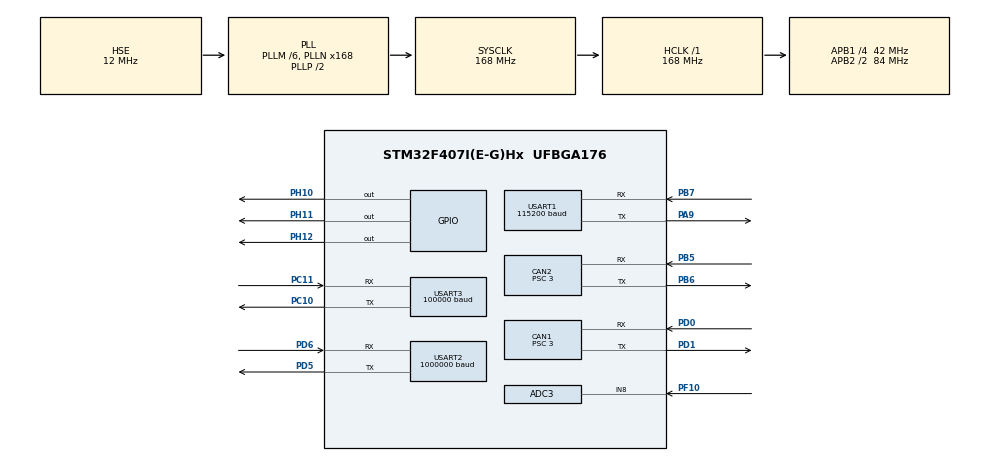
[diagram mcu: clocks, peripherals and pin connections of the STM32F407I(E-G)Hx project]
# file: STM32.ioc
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ADC3.Channel-1\#ChannelRegularConversion=ADC_CHANNEL_8
ADC3.EnableAnalogWatchDog=false
ADC3.ExternalTrigConv=ADC_EXTERNALTRIGCONV_T3_TRGO
ADC3.NbrOfConversionFlag=1
ADC3.Rank-1\#ChannelRegularConversion=1
ADC3.SamplingTime-1\#ChannelRegularConversion=ADC_SAMPLETIME_28CYCLES
CAN1.ABOM=ENABLE
CAN1.BS1=CAN_BS1_10TQ
CAN1.BS2=CAN_BS2_3TQ
CAN1.CalculateBaudRate=1000000
CAN1.CalculateTimeBit=1000
CAN1.CalculateTimeQuantum=71.42857142857143
CAN1.Prescaler=3
CAN2.ABOM=ENABLE
CAN2.BS1=CAN_BS1_10TQ
CAN2.BS2=CAN_BS2_3TQ
CAN2.CalculateBaudRate=1000000
CAN2.CalculateTimeBit=1000
CAN2.CalculateTimeQuantum=71.42857142857143
CAN2.Prescaler=3
Dma.Request0=USART3_RX
Dma.Request1=USART3_TX
Dma.USART3_RX.0.Direction=DMA_PERIPH_TO_MEMORY
Dma.USART3_RX.0.FIFOMode=DMA_FIFOMODE_DISABLE
Dma.USART3_RX.0.Instance=DMA1_Stream1
Dma.USART3_RX.0.MemDataAlignment=DMA_MDATAALIGN_BYTE
Dma.USART3_RX.0.MemInc=DMA_MINC_ENABLE
Dma.USART3_RX.0.Mode=DMA_NORMAL
Dma.USART3_RX.0.PeriphDataAlignment=DMA_PDATAALIGN_BYTE
Dma.USART3_RX.0.PeriphInc=DMA_PINC_DISABLE
Dma.USART3_RX.0.Priority=DMA_PRIORITY_LOW
Dma.USART3_TX.1.Direction=DMA_MEMORY_TO_PERIPH
Dma.USART3_TX.1.FIFOMode=DMA_FIFOMODE_DISABLE
Dma.USART3_TX.1.Instance=DMA1_Stream3
Dma.USART3_TX.1.MemDataAlignment=DMA_MDATAALIGN_BYTE
Dma.USART3_TX.1.MemInc=DMA_MINC_ENABLE
Dma.USART3_TX.1.Mode=DMA_NORMAL
Dma.USART3_TX.1.PeriphDataAlignment=DMA_PDATAALIGN_BYTE
Dma.USART3_TX.1.PeriphInc=DMA_PINC_DISABLE
Dma.USART3_TX.1.Priority=DMA_PRIORITY_LOW
Mcu.Family=STM32F4
Mcu.Name=STM32F407I(E-G)Hx
Mcu.Package=UFBGA176
NVIC.CAN1_RX0_IRQn=true\:0\:0\:false\:false\:true\:true\:true\:true
NVIC.CAN1_RX1_IRQn=true\:0\:0\:false\:false\:true\:true\:true\:true
NVIC.CAN1_SCE_IRQn=true\:0\:0\:false\:false\:true\:true\:true\:true
NVIC.CAN1_TX_IRQn=true\:0\:0\:false\:false\:true\:true\:true\:true
NVIC.CAN2_RX0_IRQn=true\:0\:0\:false\:false\:true\:true\:true\:true
NVIC.CAN2_RX1_IRQn=true\:0\:0\:false\:false\:true\:true\:true\:true
NVIC.CAN2_SCE_IRQn=true\:0\:0\:false\:false\:true\:true\:true\:true
NVIC.CAN2_TX_IRQn=true\:0\:0\:false\:false\:true\:true\:true\:true
NVIC.DMA1_Stream1_IRQn=true\:0\:0\:false\:false\:true\:false\:true\:true
NVIC.DMA1_Stream3_IRQn=true\:0\:0\:false\:false\:true\:false\:true\:true
NVIC.PriorityGroup=NVIC_PRIORITYGROUP_4
NVIC.TIM6_DAC_IRQn=true\:0\:0\:false\:false\:true\:true\:true\:true
NVIC.TIM7_IRQn=true\:0\:0\:false\:false\:true\:true\:true\:true
NVIC.USART1_IRQn=true\:0\:0\:false\:false\:true\:true\:true\:true
NVIC.USART2_IRQn=true\:0\:0\:false\:false\:true\:true\:true\:true
NVIC.USART3_IRQn=true\:0\:0\:false\:false\:true\:true\:true\:true
PA10.Signal=USB_OTG_FS_ID
PA11.Signal=USB_OTG_FS_DM
PA13.Mode=Serial_Wire
PA13.Signal=SYS_JTMS-SWDIO
PA14.Mode=Serial_Wire
PA14.Signal=SYS_JTCK-SWCLK
PA9.Mode=Asynchronous
PA9.Signal=USART1_TX
PB5.Mode=CAN_Activate
PB5.Signal=CAN2_RX
PB6.Mode=CAN_Activate
PB6.Signal=CAN2_TX
PB7.Mode=Asynchronous
PB7.Signal=USART1_RX
PC10.Mode=Asynchronous
PC10.Signal=USART3_TX
PC11.Mode=Asynchronous
PC11.Signal=USART3_RX
PC8.Signal=S_TIM3_CH3
PD0.Mode=CAN_Activate
PD0.Signal=CAN1_RX
PD1.Mode=CAN_Activate
PD1.Signal=CAN1_TX
PD14.Signal=S_TIM4_CH3
PD5.Mode=Asynchronous
PD5.Signal=USART2_TX
PD6.Mode=Asynchronous
PD6.Signal=USART2_RX
PF10.Mode=IN8
PF10.Signal=ADC3_IN8
PG14.Signal=USART6_TX
PG9.Signal=USART6_RX
PH0-OSC_IN.Mode=HSE-External-Oscillator
PH0-OSC_IN.Signal=RCC_OSC_IN
PH1-OSC_OUT.Mode=HSE-External-Oscillator
PH1-OSC_OUT.Signal=RCC_OSC_OUT
PH10.Signal=GPIO_Output
PH11.Signal=GPIO_Output
PH12.Signal=GPIO_Output
ProjectManager.HeapSize=0x1000
ProjectManager.StackSize=0x2000
ProjectManager.TargetToolchain=MDK-ARM V5.32
RCC.48MHZClocksFreq_Value=48000000
RCC.AHBFreq_Value=168000000
RCC.APB1CLKDivider=RCC_HCLK_DIV4
RCC.APB1Freq_Value=42000000
RCC.APB1TimFreq_Value=84000000
RCC.APB2CLKDivider=RCC_HCLK_DIV2
RCC.APB2Freq_Value=84000000
RCC.APB2TimFreq_Value=168000000
RCC.CortexFreq_Value=168000000
RCC.HCLKFreq_Value=168000000
RCC.HSE_VALUE=12000000
RCC.HSI_VALUE=16000000
RCC.LSE_VALUE=32768
RCC.PLLM=6
RCC.PLLN=168
RCC.PLLQ=7
RCC.PLLSourceVirtual=RCC_PLLSOURCE_HSE
RCC.SYSCLKFreq_VALUE=168000000
RCC.SYSCLKSource=RCC_SYSCLKSOURCE_PLLCLK
RCC.VCOOutputFreq_Value=336000000
SH.S_TIM3_CH3.0=TIM3_CH3
SH.S_TIM4_CH3.0=TIM4_CH3
TIM3.TIM_MasterOutputTrigger=TIM_TRGO_UPDATE
TIM4.AutoReloadPreload=TIM_AUTORELOAD_PRELOAD_ENABLE
TIM5.Period=100-1
TIM6.AutoReloadPreload=TIM_AUTORELOAD_PRELOAD_DISABLE
TIM6.Period=1000-1
TIM6.Prescaler=84-1
TIM6.TIM_MasterOutputTrigger=TIM_TRGO_RESET
TIM7.AutoReloadPreload=TIM_AUTORELOAD_PRELOAD_DISABLE
TIM7.Period=1000-1
TIM7.Prescaler=84-1
USART1.BaudRate=115200
USART1.VirtualMode=VM_ASYNC
USART2.BaudRate=1000000
USART2.VirtualMode=VM_ASYNC
USART3.BaudRate=100000
USART3.VirtualMode=VM_ASYNC
VP_IWDG_VS_IWDG.Mode=IWDG_Activate
VP_TIM3_VS_ClockSourceINT.Mode=Internal
VP_TIM4_VS_ClockSourceINT.Mode=Internal
VP_TIM5_VS_ClockSourceINT.Mode=Internal
VP_TIM6_VS_ClockSourceINT.Mode=Enable_Timer
VP_TIM7_VS_ClockSourceINT.Mode=Enable_Timer
board=custom

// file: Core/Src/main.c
/* USER CODE BEGIN Header */
/**
  ******************************************************************************
  * @file           : main.c
  * @brief          : Main program body
  ******************************************************************************
  * @attention
  *
  * Copyright (c) 2023 STMicroelectronics.
  * All rights reserved.
  *
  * This software is licensed under terms that can be found in the LICENSE file
  * in the root directory of this software component.
  * If no LICENSE file comes with this software, it is provided AS-IS.
  *
  ******************************************************************************
  */
/* USER CODE END Header */
#include "main.h"
#include "adc.h"
#include "can.h"
#include "dma.h"
#include "iwdg.h"
#include "tim.h"
#include "usart.h"
#include "gpio.h"
#include "string.h"
#include "remote_control.h"

void SystemClock_Config(void);

int main(void)
{

  /* MCU Configuration--------------------------------------------------------*/

  /* Reset of all peripherals, Initializes the Flash interface and the Systick. */
  HAL_Init();

  /* Configure the system clock */
  SystemClock_Config();

  /* Initialize all configured peripherals */
  MX_GPIO_Init();
  MX_DMA_Init();
  MX_ADC3_Init();
  MX_CAN1_Init();
  MX_CAN2_Init();
  //MX_IWDG_Init();
  MX_TIM3_Init();
  MX_TIM4_Init();
  MX_TIM5_Init();
  MX_TIM6_Init();
  MX_TIM7_Init();
  MX_USART1_UART_Init();
  MX_USART2_UART_Init();
  MX_USART3_UART_Init();
  /* USER CODE BEGIN 2 */
    canFilterInit();
    HAL_UART_Receive_IT(&huart3,buffer,18);
  /* USER CODE END 2 */

  /* Infinite loop */
  while (1)
  {

  }
}

void SystemClock_Config(void)
{
  RCC_OscInitTypeDef RCC_OscInitStruct = {0};
  RCC_ClkInitTypeDef RCC_ClkInitStruct = {0};

  /** Configure the main internal regulator output voltage
  */
  __HAL_RCC_PWR_CLK_ENABLE();
  __HAL_PWR_VOLTAGESCALING_CONFIG(PWR_REGULATOR_VOLTAGE_SCALE1);

  /** Initializes the RCC Oscillators according to the specified parameters
  * in the RCC_OscInitTypeDef structure.
  */
  RCC_OscInitStruct.OscillatorType = RCC_OSCILLATORTYPE_LSI|RCC_OSCILLATORTYPE_HSE;
  RCC_OscInitStruct.HSEState = RCC_HSE_ON;
  RCC_OscInitStruct.LSIState = RCC_LSI_ON;
  RCC_OscInitStruct.PLL.PLLState = RCC_PLL_ON;
  RCC_OscInitStruct.PLL.PLLSource = RCC_PLLSOURCE_HSE;
  RCC_OscInitStruct.PLL.PLLM = 6;
  RCC_OscInitStruct.PLL.PLLN = 168;
  RCC_OscInitStruct.PLL.PLLP = RCC_PLLP_DIV2;
  RCC_OscInitStruct.PLL.PLLQ = 7;
  if (HAL_RCC_OscConfig(&RCC_OscInitStruct) != HAL_OK)
  {
    Error_Handler();
  }

  /** Initializes the CPU, AHB and APB buses clocks
  */
  RCC_ClkInitStruct.ClockType = RCC_CLOCKTYPE_HCLK|RCC_CLOCKTYPE_SYSCLK
                              |RCC_CLOCKTYPE_PCLK1|RCC_CLOCKTYPE_PCLK2;
  RCC_ClkInitStruct.SYSCLKSource = RCC_SYSCLKSOURCE_PLLCLK;
  RCC_ClkInitStruct.AHBCLKDivider = RCC_SYSCLK_DIV1;
  RCC_ClkInitStruct.APB1CLKDivider = RCC_HCLK_DIV4;
  RCC_ClkInitStruct.APB2CLKDivider = RCC_HCLK_DIV2;

  if (HAL_RCC_ClockConfig(&RCC_ClkInitStruct, FLASH_LATENCY_5) != HAL_OK)
  {
    Error_Handler();
  }
}

void Error_Handler(void)
{
  __disable_irq();
  while (1)
  {
  }
}
